# WE2_S register map
Vendor: ARM Ltd.; Series: ARMv8.1-M Mainline; File version: 1.0
CPU: CM55 r1p1, little endian, MPU, FPU, double-precision FPU, DSP, VTOR, 3 interrupt priority bits
Registers are 32-bit, read-write, reset 0x0 unless marked. A register's access mark holds for its fields unless they carry their own. Offsets are from the block's base; [hi:lo] are bit positions; {n}, {i} and the like mark numbered series.

## PWM0
Base 0x52003000
Same registers: PWM1 0x52003040, PWM2 0x52003080
0x00 pwm_ctrl — pwm ctrl address
0x04 pwm_cycle — pwm cycle count address
0x08 pwm_duty — pwm duty cycle address
0x0C pwm_pulse — pwm pulse count address
0x10 pwm_dbg_sel — pwm debug signal select address
0x14 pwm_int_clr — pwm interrupt clear address
0x18 pwm_dbg_cycle ro — pwm number of cycle count addresss
0x1C pwm_dbg_hlbeat ro — pwm number of high level beats address
0x20 pwm_dbg_state ro

## RTC0
Base 0x56107000
Same registers: RTC1 0x56108000, RTC2 0x56109000
0x00 RTC_DR — Data read register
0x04 RTC_MR — Match register
0x08 RTC_LR — Data load register
0x0C RTC_CR — Control register
0x10 RTC_IMSC — Interrupt mask and set register
0x14 RTC_RIS — Raw interrupt status register
0x18 RTC_MIS — Masked interrupt status register
0x1C RTC_ICR — Interrupt clear register

## SCU_SB
Base 0x56006000
0x00 SCU_I2C2AHB_PINMUX
0x04 SCU_SENSOR_PINMUX
0x08 SCU_SENSOR_PCLKO_PINMUX
0x14 SCU_TIMER1_CLK_DIV
0x130 SCU_WATCHDOG_CLK_EN
0x134 SCU_WATCHDOG0_CLK_DIV
0x138 SCU_WATCHDOG1_CLK_DIV
0x13C SCU_TIMER_CLK_EN
0x140 SCU_TIMER0_CLK_DIV
{0x140+4i} SCU_TIMER{i}_CLK_DIV (i=2..8)
0x164 SCU_TIMER_INT_AUTOCLEAR
0x870 SCU_APB1NS_PPC_CFG_APNS
0x874 SCU_APB1NS_PPC_CFG_INT
0x878 SCU_APB1PS_PPC_CFG_APNS
0x87C SCU_APB1PS_PPC_CFG_INT

## SCU_AON
Base 0x56100000
0x00 AON_CLK_CTRL
0x04 SB_CLK_CTRL
  [31:0] VAL
0x08 SCU_REG_LSC_BUS_CK_CTRL_15_0
  [15:0] VAL
0x0C SCU_REG_LSC_BUS_CK_CTRL_31_16
  [15:0] VAL
{0x10+8i} SCU_REG_LSC_PERI_CK_CTRL{i}_15_0 (i=0..2)
  [15:0] VAL
{0x14+8i} SCU_REG_LSC_PERI_CK_CTRL{i}_31_16 (i=0..2)
  [15:0] VAL
0x28 DP_IMAGEPATH_RXPCLK
0x2C SB_CLK_ENABLE
0x30 SCU_REG_HSC_PERI_CK_CTRL0_15_0
  [15:0] VAL
0x34 SCU_REG_HSC_PERI_CK_CTRL1_24_16
  [15:0] VAL
0x40 SCU_REG_LSC_CLK_ENABLE_15_0
  [15:0] VAL
0x44 SCU_REG_LSC_CLK_ENABLE_31_16
  [15:0] VAL
0x48 SCU_REG_HSC_CLK_ENABLE_15_0
  [15:0] VAL
0x4C SCU_REG_HSC_CLK_ENABLE_31_16
  [15:0] VAL
0x60 SCU_REG_AON_SB_SW_RESETN
{0x100+0x10*i} SCU_RTC{i}_RTCRSTN (i=0..2)
{0x104+0x10*i} SCU_RTC{i}_CKGEN_ENABLE (i=0..2)
{0x108+0x10*i} SCU_RTC{i}_RISE_COUNT (i=0..2)
{0x10C+0x10*i} SCU_RTC{i}_CYCLE_COUNT (i=0..2)
0x210 SCU_CM55S_nSYSRESET
0x214 SCU_U55_nSYSRESET
0x218 SCU_CM55M_nSYSRESET
0x220 SCU_CM55S_PORRESET
0x228 SCU_CM55M_PORRESET
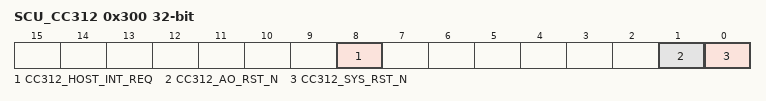
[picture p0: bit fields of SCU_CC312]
0x300 SCU_CC312
  [8] CC312_HOST_INT_REQ, [1] CC312_AO_RST_N, [0] CC312_SYS_RST_N
0x304 SCU_REG_IMG_CLK_WAKEUP_SEL
0x310 SCU_REG_I2C2AHB_DBG_ID
0x314 SCU_REG_I2C2AHB_FLASHWR_ID
0x320 anti_tamp_en
0x324 anti_int_ctrl
0x328 anti_int_status
0x32C anti_tam_det_ctrl
0x330 anti_clk_moni_ctrl
0x334 anti_clk_moni_thr
0x500 SCU_REG_APB1_AON_PPC_CFG_AP_NONSEC
0x504 SCU_REG_APB1_AON_PPC_CFG_IRQ_RSP
0x510 SCU_SRAM0_MPC_CFG_APNSINT
0x514 SCU_SRAM1_MPC_CFG_APNSINT
0x518 SCU_DP_DMA_AHBMSC_IDAUCFG
0x51C SCU_APB2_PPC_CFG_AP_MIPIRX_CTRL
0x600 SCU_REG_CORE_VOLT
0x700 SCU_REG_RC24M1M_CFG
0x704 SCU_REG_RC96M48M_CFG
0x708 SCU_REG_RC32K1K_CFG_15_0
  [15:0] VAL
0x70C SCU_REG_RC32K1K_CFG_31_16
  [15:0] VAL
0x710 SCU_REG_PLLEN_CFG
{0x710+4i} SCU_REG_PLLARG_CFG{i} (i=1..6)
0x72C SCU_REG_BORPORTEST
0x730 SCU_REG_XTAL32K_CFG
0x734 SCU_REG_XTAL24M_CFG
0x800 SCU_CM55M_IDAU
0x804 SCU_CM55S_IDAU
0xC00 SCU_CM55M_INITSVTOR
0xC04 SCU_CM55M_INITNSVTOR
0xC08 SCU_CM55M_CPUWAIT
0xC0C SCU_CM55M_LOCK
0xD00 SCU_CM55S_INITSVTOR
0xD04 SCU_CM55S_INITNSVTOR
0xD08 SCU_CM55S_CPUWAIT
0xD0C SCU_CM55S_LOCK
0xE00 SCU_U55_POR
0xF20 SCU_BOOTOPT_TESTMODE
0xFF0 SCU_FPGA_VERSION1
0xFF4 SCU_FPGA_VERSION2

## SCU_HSC
Base 0x53070000
0x808 SCU_U55_AXIMSC_IDAU
0x80C SCU_U55_AXIMSC_CFG
0x810 SCU_DMA0_AHBMSC_IDAUCFG
0x814 SCU_DMA1_AHBMSC_IDAUCFG
0x82C SCU_I3CHC_MSC_IDAUCFG
0x830 SCU_SDIO_MSC_IDAUCFG
0x840 SCU_DWC_PPC_CFG_APNS
0x844 SCU_DWC_PPC_CFG_INT
0x848 SCU_ISP_PPC_CFG_APNS
0x84C SCU_ISP_PPC_CFG_INT
0x858 SCU_AHB1M4_PPC_CFG_APNS
0x85C SCU_AHB1M4_PPC_CFG_INT
0x880 SCU_APB2_PPC_CFG_AP
0x884 SCU_APB2_PPC_CFG_NS
0x888 SCU_APB2_PPC_CFG_INT
0x8A0 SCU_ROM_PPC_CFG_APNSINT
0x8A4 SCU_QOSPI_MPC_CFG_APNSINT
0xA00 SCU_CORESIGHT_DBG_EN
0xB00 SCU_ISP_XIP_SPICACHE
0xB04 SCU_OSPI_XIP_EN_SLAVE
0xB08 SCU_OSPI_RESETN
0xB10 SCU_SDIO_HWINIT_ITCFVAL

## Notices in the file
Copyright (C) 2012 - 2020 Arm Limited. All rights reserved.
Purpose: System Viewer Description (SVD) Example (Schema Version 1.1)
This is a description of a none-existent and incomplete device
for demonstration purposes only.
Redistribution and use in source and binary forms, with or without
modification, are permitted provided that the following conditions are met:
- Redistributions of source code must retain the above copyright
notice, this list of conditions and the following disclaimer.
- Redistributions in binary form must reproduce the above copyright
notice, this list of conditions and the following disclaimer in the
documentation and/or other materials provided with the distribution.
- Neither the name of ARM nor the names of its contributors may be used
to endorse or promote products derived from this software without
specific prior written permission.
THIS SOFTWARE IS PROVIDED BY THE COPYRIGHT HOLDERS AND CONTRIBUTORS "AS IS"
AND ANY EXPRESS OR IMPLIED WARRANTIES, INCLUDING, BUT NOT LIMITED TO, THE
IMPLIED WARRANTIES OF MERCHANTABILITY AND FITNESS FOR A PARTICULAR PURPOSE
ARE DISCLAIMED. IN NO EVENT SHALL COPYRIGHT HOLDERS AND CONTRIBUTORS BE
LIABLE FOR ANY DIRECT, INDIRECT, INCIDENTAL, SPECIAL, EXEMPLARY, OR
CONSEQUENTIAL DAMAGES (INCLUDING, BUT NOT LIMITED TO, PROCUREMENT OF
SUBSTITUTE GOODS OR SERVICES; LOSS OF USE, DATA, OR PROFITS; OR BUSINESS
INTERRUPTION) HOWEVER CAUSED AND ON ANY THEORY OF LIABILITY, WHETHER IN
CONTRACT, STRICT LIABILITY, OR TORT (INCLUDING NEGLIGENCE OR OTHERWISE)
ARISING IN ANY WAY OUT OF THE USE OF THIS SOFTWARE, EVEN IF ADVISED OF THE
POSSIBILITY OF SUCH DAMAGE.
